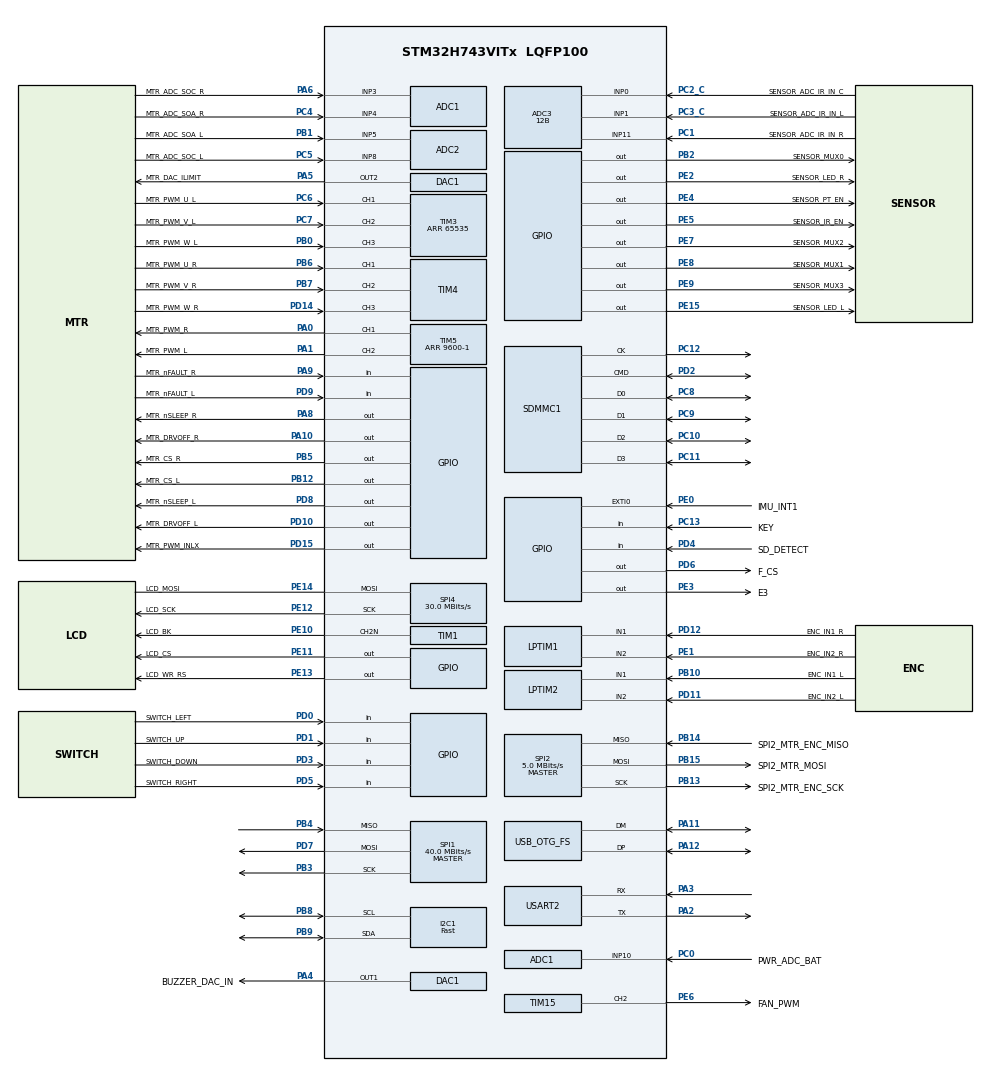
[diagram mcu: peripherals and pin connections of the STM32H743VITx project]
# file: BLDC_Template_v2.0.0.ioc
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ADC1.Channel-3\#ChannelRegularConversion=ADC_CHANNEL_10
ADC1.ClockPrescaler=ADC_CLOCK_ASYNC_DIV4
ADC1.ConversionDataManagement=ADC_CONVERSIONDATA_DMA_CIRCULAR
ADC1.EOCSelection=ADC_EOC_SEQ_CONV
ADC1.EnableInjectedConversion=ENABLE
ADC1.EnableInjectedOversampling=ENABLE
ADC1.ExternalTrigConv=ADC_EXTERNALTRIG_T4_TRGO
ADC1.ExternalTrigInjecConv=ADC_EXTERNALTRIGINJEC_T4_TRGO
ADC1.InjNumberOfConversion=2
ADC1.InjOversamplingRatio=1
ADC1.InjOversamplingRightShift=ADC_RIGHTBITSHIFT_NONE
ADC1.InjectedChannel-6\#ChannelInjectedConversion=ADC_CHANNEL_4
ADC1.InjectedChannel-7\#ChannelInjectedConversion=ADC_CHANNEL_3
ADC1.InjectedOffsetNumber-6\#ChannelInjectedConversion=ADC_OFFSET_NONE
ADC1.InjectedOffsetNumber-7\#ChannelInjectedConversion=ADC_OFFSET_NONE
ADC1.InjectedOffsetSaturation-6\#ChannelInjectedConversion=DISABLE
ADC1.InjectedOffsetSaturation-7\#ChannelInjectedConversion=DISABLE
ADC1.InjectedOffsetSignedSaturation-6\#ChannelInjectedConversion=DISABLE
ADC1.InjectedOffsetSignedSaturation-7\#ChannelInjectedConversion=DISABLE
ADC1.InjectedRank-6\#ChannelInjectedConversion=1
ADC1.InjectedRank-7\#ChannelInjectedConversion=2
ADC1.InjectedSamplingTime-6\#ChannelInjectedConversion=ADC_SAMPLETIME_8CYCLES_5
ADC1.InjectedSamplingTime-7\#ChannelInjectedConversion=ADC_SAMPLETIME_8CYCLES_5
ADC1.NbrOfConversion=1
ADC1.NbrOfConversionFlag=1
ADC1.OffsetNumber-3\#ChannelRegularConversion=ADC_OFFSET_NONE
ADC1.OffsetSignedSaturation-3\#ChannelRegularConversion=DISABLE
ADC1.OversamplingMode=ENABLE
ADC1.Rank-3\#ChannelRegularConversion=1
ADC1.Ratio=4
ADC1.RightBitShift=ADC_RIGHTBITSHIFT_2
ADC1.SamplingTime-3\#ChannelRegularConversion=ADC_SAMPLETIME_16CYCLES_5
ADC1.master=1
ADC2.Channel-2\#ChannelRegularConversion=ADC_CHANNEL_10
ADC2.ClockPrescaler=ADC_CLOCK_ASYNC_DIV4
ADC2.ConversionDataManagement=ADC_CONVERSIONDATA_DMA_CIRCULAR
ADC2.EOCSelection=ADC_EOC_SEQ_CONV
ADC2.EnableInjectedConversion=ENABLE
ADC2.EnableInjectedOversampling=ENABLE
ADC2.ExternalTrigConv=ADC_EXTERNALTRIG_T3_TRGO
ADC2.ExternalTrigInjecConv=ADC_EXTERNALTRIGINJEC_T3_TRGO
ADC2.InjNumberOfConversion=2
ADC2.InjOversamplingRatio=1
ADC2.InjOversamplingRightShift=ADC_RIGHTBITSHIFT_NONE
ADC2.InjectedChannel-5\#ChannelInjectedConversion=ADC_CHANNEL_5
ADC2.InjectedChannel-6\#ChannelInjectedConversion=ADC_CHANNEL_8
ADC2.InjectedOffsetNumber-5\#ChannelInjectedConversion=ADC_OFFSET_NONE
ADC2.InjectedOffsetNumber-6\#ChannelInjectedConversion=ADC_OFFSET_NONE
ADC2.InjectedOffsetSaturation-5\#ChannelInjectedConversion=DISABLE
ADC2.InjectedOffsetSaturation-6\#ChannelInjectedConversion=DISABLE
ADC2.InjectedOffsetSignedSaturation-5\#ChannelInjectedConversion=DISABLE
ADC2.InjectedOffsetSignedSaturation-6\#ChannelInjectedConversion=DISABLE
ADC2.InjectedRank-5\#ChannelInjectedConversion=1
ADC2.InjectedRank-6\#ChannelInjectedConversion=2
ADC2.InjectedSamplingTime-5\#ChannelInjectedConversion=ADC_SAMPLETIME_8CYCLES_5
ADC2.InjectedSamplingTime-6\#ChannelInjectedConversion=ADC_SAMPLETIME_8CYCLES_5
ADC2.NbrOfConversion=1
ADC2.NbrOfConversionFlag=1
ADC2.OffsetNumber-2\#ChannelRegularConversion=ADC_OFFSET_NONE
ADC2.OffsetSignedSaturation-2\#ChannelRegularConversion=DISABLE
ADC2.OversamplingMode=ENABLE
ADC2.Rank-2\#ChannelRegularConversion=1
ADC2.Ratio=4
ADC2.RightBitShift=ADC_RIGHTBITSHIFT_2
ADC2.SamplingTime-2\#ChannelRegularConversion=ADC_SAMPLETIME_16CYCLES_5
ADC3.Channel-10\#ChannelRegularConversion=ADC_CHANNEL_1
ADC3.Channel-11\#ChannelRegularConversion=ADC_CHANNEL_11
ADC3.Channel-2\#ChannelRegularConversion=ADC_CHANNEL_0
ADC3.Channel-3\#ChannelRegularConversion=ADC_CHANNEL_0
ADC3.Channel-4\#ChannelRegularConversion=ADC_CHANNEL_0
ADC3.Channel-5\#ChannelRegularConversion=ADC_CHANNEL_0
ADC3.Channel-6\#ChannelRegularConversion=ADC_CHANNEL_0
ADC3.Channel-7\#ChannelRegularConversion=ADC_CHANNEL_0
ADC3.Channel-8\#ChannelRegularConversion=ADC_CHANNEL_0
ADC3.Channel-9\#ChannelRegularConversion=ADC_CHANNEL_0
ADC3.ClockPrescaler=ADC_CLOCK_ASYNC_DIV4
ADC3.ContinuousConvMode=DISABLE
ADC3.ConversionDataManagement=ADC_CONVERSIONDATA_DMA_CIRCULAR
ADC3.DiscontinuousConvMode=ENABLE
ADC3.EOCSelection=ADC_EOC_SINGLE_CONV
ADC3.ExternalTrigConv=ADC_EXTERNALTRIG_T2_TRGO
ADC3.NbrOfConversion=10
ADC3.NbrOfConversionFlag=1
ADC3.OffsetNumber-10\#ChannelRegularConversion=ADC_OFFSET_NONE
ADC3.OffsetNumber-11\#ChannelRegularConversion=ADC_OFFSET_NONE
ADC3.OffsetNumber-2\#ChannelRegularConversion=ADC_OFFSET_NONE
ADC3.OffsetNumber-3\#ChannelRegularConversion=ADC_OFFSET_NONE
ADC3.OffsetNumber-4\#ChannelRegularConversion=ADC_OFFSET_NONE
ADC3.OffsetNumber-5\#ChannelRegularConversion=ADC_OFFSET_NONE
ADC3.OffsetNumber-6\#ChannelRegularConversion=ADC_OFFSET_NONE
ADC3.OffsetNumber-7\#ChannelRegularConversion=ADC_OFFSET_NONE
ADC3.OffsetNumber-8\#ChannelRegularConversion=ADC_OFFSET_NONE
ADC3.OffsetNumber-9\#ChannelRegularConversion=ADC_OFFSET_NONE
ADC3.OffsetSignedSaturation-2\#ChannelRegularConversion=DISABLE
ADC3.Overrun=ADC_OVR_DATA_PRESERVED
ADC3.OversamplingMode=ENABLE
ADC3.OversamplingStopReset=ADC_REGOVERSAMPLING_RESUMED_MODE
ADC3.Rank-10\#ChannelRegularConversion=9
ADC3.Rank-11\#ChannelRegularConversion=10
ADC3.Rank-2\#ChannelRegularConversion=1
ADC3.Rank-3\#ChannelRegularConversion=2
ADC3.Rank-4\#ChannelRegularConversion=3
ADC3.Rank-5\#ChannelRegularConversion=4
ADC3.Rank-6\#ChannelRegularConversion=5
ADC3.Rank-7\#ChannelRegularConversion=6
ADC3.Rank-8\#ChannelRegularConversion=7
ADC3.Rank-9\#ChannelRegularConversion=8
ADC3.Ratio=2
ADC3.Resolution=ADC_RESOLUTION_12B
ADC3.RightBitShift=ADC_RIGHTBITSHIFT_1
ADC3.SamplingTime-10\#ChannelRegularConversion=ADC_SAMPLETIME_8CYCLES_5
ADC3.SamplingTime-11\#ChannelRegularConversion=ADC_SAMPLETIME_8CYCLES_5
ADC3.SamplingTime-2\#ChannelRegularConversion=ADC_SAMPLETIME_8CYCLES_5
ADC3.SamplingTime-3\#ChannelRegularConversion=ADC_SAMPLETIME_8CYCLES_5
ADC3.SamplingTime-4\#ChannelRegularConversion=ADC_SAMPLETIME_8CYCLES_5
ADC3.SamplingTime-5\#ChannelRegularConversion=ADC_SAMPLETIME_8CYCLES_5
ADC3.SamplingTime-6\#ChannelRegularConversion=ADC_SAMPLETIME_8CYCLES_5
ADC3.SamplingTime-7\#ChannelRegularConversion=ADC_SAMPLETIME_8CYCLES_5
ADC3.SamplingTime-8\#ChannelRegularConversion=ADC_SAMPLETIME_8CYCLES_5
ADC3.SamplingTime-9\#ChannelRegularConversion=ADC_SAMPLETIME_8CYCLES_5
ADC3.TriggeredMode=ADC_TRIGGEREDMODE_SINGLE_TRIGGER
Bdma.ADC3.0.Direction=DMA_PERIPH_TO_MEMORY
Bdma.ADC3.0.EventEnable=DISABLE
Bdma.ADC3.0.Instance=BDMA_Channel0
Bdma.ADC3.0.MemDataAlignment=DMA_MDATAALIGN_HALFWORD
Bdma.ADC3.0.MemInc=DMA_MINC_ENABLE
Bdma.ADC3.0.Mode=DMA_CIRCULAR
Bdma.ADC3.0.PeriphDataAlignment=DMA_PDATAALIGN_HALFWORD
Bdma.ADC3.0.PeriphInc=DMA_PINC_DISABLE
Bdma.ADC3.0.Polarity=HAL_DMAMUX_REQ_GEN_RISING
Bdma.ADC3.0.Priority=DMA_PRIORITY_VERY_HIGH
Bdma.ADC3.0.RequestNumber=1
Bdma.ADC3.0.SignalID=NONE
Bdma.ADC3.0.SyncEnable=DISABLE
Bdma.ADC3.0.SyncPolarity=HAL_DMAMUX_SYNC_NO_EVENT
Bdma.ADC3.0.SyncRequestNumber=1
Bdma.ADC3.0.SyncSignalID=NONE
Bdma.Request0=ADC3
Bdma.RequestsNb=1
CORTEX_M7.AccessPermission_S-Cortex_Memory_Protection_Unit_Region1_Settings_S=MPU_REGION_FULL_ACCESS
CORTEX_M7.AccessPermission_Spec=MPU_REGION_FULL_ACCESS
CORTEX_M7.BaseAddress_S-Cortex_Memory_Protection_Unit_Region1_Settings_S=0x38000000
CORTEX_M7.BaseAddress_Spec=0x30040000
CORTEX_M7.CPU_DCache=Enabled
CORTEX_M7.CPU_ICache=Enabled
CORTEX_M7.DisableExec_S-Cortex_Memory_Protection_Unit_Region1_Settings_S=MPU_INSTRUCTION_ACCESS_DISABLE
CORTEX_M7.Enable_S-Cortex_Memory_Protection_Unit_Region1_Settings_S=MPU_REGION_ENABLE
CORTEX_M7.IsShareable_S-Cortex_Memory_Protection_Unit_Region1_Settings_S=MPU_ACCESS_SHAREABLE
CORTEX_M7.MPU_Control=MPU_PRIVILEGED_DEFAULT
CORTEX_M7.Size_S-Cortex_Memory_Protection_Unit_Region1_Settings_S=MPU_REGION_SIZE_64KB
CORTEX_M7.Size_Spec=MPU_REGION_SIZE_32KB
CORTEX_M7.SubRegionDisable_Spec=0x0
CORTEX_M7.TypeExtField_S-Cortex_Memory_Protection_Unit_Region1_Settings_S=MPU_TEX_LEVEL1
CORTEX_M7.TypeExtField_Spec=MPU_TEX_LEVEL1
CORTEX_M7.default_mode_Activation=1
DAC1.DAC_Channel-DAC_OUT1=DAC_CHANNEL_1
DAC1.DAC_Channel-DAC_OUT2=DAC_CHANNEL_2
DAC1.DAC_Trigger-DAC_OUT1=DAC_TRIGGER_T6_TRGO
Dma.ADC1.3.Direction=DMA_PERIPH_TO_MEMORY
Dma.ADC1.3.EventEnable=DISABLE
Dma.ADC1.3.FIFOMode=DMA_FIFOMODE_DISABLE
Dma.ADC1.3.Instance=DMA1_Stream3
Dma.ADC1.3.MemDataAlignment=DMA_MDATAALIGN_HALFWORD
Dma.ADC1.3.MemInc=DMA_MINC_ENABLE
Dma.ADC1.3.Mode=DMA_CIRCULAR
Dma.ADC1.3.PeriphDataAlignment=DMA_PDATAALIGN_HALFWORD
Dma.ADC1.3.PeriphInc=DMA_PINC_DISABLE
Dma.ADC1.3.Polarity=HAL_DMAMUX_REQ_GEN_RISING
Dma.ADC1.3.Priority=DMA_PRIORITY_VERY_HIGH
Dma.ADC1.3.RequestNumber=1
Dma.ADC1.3.SignalID=NONE
Dma.ADC1.3.SyncEnable=DISABLE
Dma.ADC1.3.SyncPolarity=HAL_DMAMUX_SYNC_NO_EVENT
Dma.ADC1.3.SyncRequestNumber=1
Dma.ADC1.3.SyncSignalID=NONE
Dma.ADC2.2.Direction=DMA_PERIPH_TO_MEMORY
Dma.ADC2.2.EventEnable=DISABLE
Dma.ADC2.2.FIFOMode=DMA_FIFOMODE_DISABLE
Dma.ADC2.2.Instance=DMA1_Stream2
Dma.ADC2.2.MemDataAlignment=DMA_MDATAALIGN_HALFWORD
Dma.ADC2.2.MemInc=DMA_MINC_ENABLE
Dma.ADC2.2.Mode=DMA_CIRCULAR
Dma.ADC2.2.PeriphDataAlignment=DMA_PDATAALIGN_HALFWORD
Dma.ADC2.2.PeriphInc=DMA_PINC_DISABLE
Dma.ADC2.2.Polarity=HAL_DMAMUX_REQ_GEN_RISING
Dma.ADC2.2.Priority=DMA_PRIORITY_VERY_HIGH
Dma.ADC2.2.RequestNumber=1
Dma.ADC2.2.SignalID=NONE
Dma.ADC2.2.SyncEnable=DISABLE
Dma.ADC2.2.SyncPolarity=HAL_DMAMUX_SYNC_NO_EVENT
Dma.ADC2.2.SyncRequestNumber=1
Dma.ADC2.2.SyncSignalID=NONE
Dma.DAC1_CH1.1.Direction=DMA_MEMORY_TO_PERIPH
Dma.DAC1_CH1.1.EventEnable=DISABLE
Dma.DAC1_CH1.1.FIFOMode=DMA_FIFOMODE_DISABLE
Dma.DAC1_CH1.1.Instance=DMA1_Stream1
Dma.DAC1_CH1.1.MemDataAlignment=DMA_MDATAALIGN_WORD
Dma.DAC1_CH1.1.MemInc=DMA_MINC_ENABLE
Dma.DAC1_CH1.1.Mode=DMA_CIRCULAR
Dma.DAC1_CH1.1.PeriphDataAlignment=DMA_PDATAALIGN_WORD
Dma.DAC1_CH1.1.PeriphInc=DMA_PINC_DISABLE
Dma.DAC1_CH1.1.Polarity=HAL_DMAMUX_REQ_GEN_RISING
Dma.DAC1_CH1.1.Priority=DMA_PRIORITY_LOW
Dma.DAC1_CH1.1.RequestNumber=1
Dma.DAC1_CH1.1.SignalID=NONE
Dma.DAC1_CH1.1.SyncEnable=DISABLE
Dma.DAC1_CH1.1.SyncPolarity=HAL_DMAMUX_SYNC_NO_EVENT
Dma.DAC1_CH1.1.SyncRequestNumber=1
Dma.DAC1_CH1.1.SyncSignalID=NONE
Dma.I2C1_RX.4.Direction=DMA_PERIPH_TO_MEMORY
Dma.I2C1_RX.4.EventEnable=DISABLE
Dma.I2C1_RX.4.FIFOMode=DMA_FIFOMODE_DISABLE
Dma.I2C1_RX.4.Instance=DMA1_Stream4
Dma.I2C1_RX.4.MemDataAlignment=DMA_MDATAALIGN_BYTE
Dma.I2C1_RX.4.MemInc=DMA_MINC_ENABLE
Dma.I2C1_RX.4.Mode=DMA_NORMAL
Dma.I2C1_RX.4.PeriphDataAlignment=DMA_PDATAALIGN_BYTE
Dma.I2C1_RX.4.PeriphInc=DMA_PINC_DISABLE
Dma.I2C1_RX.4.Polarity=HAL_DMAMUX_REQ_GEN_RISING
Dma.I2C1_RX.4.Priority=DMA_PRIORITY_LOW
Dma.I2C1_RX.4.RequestNumber=1
Dma.I2C1_RX.4.SignalID=NONE
Dma.I2C1_RX.4.SyncEnable=DISABLE
Dma.I2C1_RX.4.SyncPolarity=HAL_DMAMUX_SYNC_NO_EVENT
Dma.I2C1_RX.4.SyncRequestNumber=1
Dma.I2C1_RX.4.SyncSignalID=NONE
Dma.Request0=SPI4_TX
Dma.Request1=DAC1_CH1
Dma.Request2=ADC2
Dma.Request3=ADC1
Dma.Request4=I2C1_RX
Dma.SPI4_TX.0.Direction=DMA_MEMORY_TO_PERIPH
Dma.SPI4_TX.0.EventEnable=DISABLE
Dma.SPI4_TX.0.FIFOMode=DMA_FIFOMODE_ENABLE
Dma.SPI4_TX.0.FIFOThreshold=DMA_FIFO_THRESHOLD_FULL
Dma.SPI4_TX.0.Instance=DMA1_Stream0
Dma.SPI4_TX.0.MemBurst=DMA_MBURST_SINGLE
Dma.SPI4_TX.0.MemDataAlignment=DMA_MDATAALIGN_BYTE
Dma.SPI4_TX.0.MemInc=DMA_MINC_ENABLE
Dma.SPI4_TX.0.Mode=DMA_NORMAL
Dma.SPI4_TX.0.PeriphBurst=DMA_PBURST_SINGLE
Dma.SPI4_TX.0.PeriphDataAlignment=DMA_PDATAALIGN_BYTE
Dma.SPI4_TX.0.PeriphInc=DMA_PINC_DISABLE
Dma.SPI4_TX.0.Polarity=HAL_DMAMUX_REQ_GEN_RISING
Dma.SPI4_TX.0.Priority=DMA_PRIORITY_LOW
Dma.SPI4_TX.0.RequestNumber=1
Dma.SPI4_TX.0.SignalID=NONE
Dma.SPI4_TX.0.SyncEnable=DISABLE
Dma.SPI4_TX.0.SyncPolarity=HAL_DMAMUX_SYNC_NO_EVENT
Dma.SPI4_TX.0.SyncRequestNumber=1
Dma.SPI4_TX.0.SyncSignalID=NONE
FATFS.BSP.number=1
FATFS.USE_DMA_CODE_SD=1
FATFS._FS_EXFAT=1
FATFS._MAX_SS=4096
FATFS._USE_LFN=1
FATFS0.BSP.STBoard=false
FATFS0.BSP.api=Unknown
FATFS0.BSP.instance=PD4
FATFS0.BSP.ip=GPIO
FATFS0.BSP.mode=Input
FATFS0.BSP.name=Detect_SDIO
FATFS0.BSP.solution=PD4
I2C1.I2C_Speed_Mode=I2C_Fast
I2C1.Timing=0x30C8172C
LPTIM1.ULPClockPolarity=LPTIM_CLOCKPOLARITY_RISING_FALLING
LPTIM2.ULPClockPolarity=LPTIM_CLOCKPOLARITY_RISING_FALLING
LPTIM3.ClockPrescaler=LPTIM_PRESCALER_DIV32
Mcu.Family=STM32H7
Mcu.Name=STM32H743VITx
Mcu.Package=LQFP100
Mcu.UserConstants=CUSTOM_HID_EPOUT_SIZE,0x40U;CUSTOM_HID_EPIN_SIZE,0x40U
NVIC.ADC3_IRQn=true\:0\:0\:false\:false\:true\:true\:true\:true
NVIC.ADC_IRQn=true\:0\:0\:false\:false\:true\:true\:true\:true
NVIC.BDMA_Channel0_IRQn=true\:0\:0\:false\:false\:true\:false\:true\:true
NVIC.DMA1_Stream0_IRQn=true\:0\:0\:false\:false\:true\:false\:true\:true
NVIC.DMA1_Stream1_IRQn=true\:0\:0\:false\:false\:true\:false\:true\:true
NVIC.DMA1_Stream2_IRQn=true\:0\:0\:false\:false\:true\:false\:true\:true
NVIC.DMA1_Stream3_IRQn=true\:0\:0\:false\:false\:true\:false\:true\:true
NVIC.DMA1_Stream4_IRQn=true\:0\:0\:false\:false\:true\:false\:true\:true
NVIC.EXTI0_IRQn=true\:0\:0\:false\:false\:true\:true\:true\:true
NVIC.I2C1_ER_IRQn=true\:0\:0\:false\:false\:true\:true\:true\:true
NVIC.I2C1_EV_IRQn=true\:0\:0\:false\:false\:true\:true\:true\:true
NVIC.LPTIM3_IRQn=true\:0\:0\:false\:false\:true\:true\:true\:true
NVIC.OTG_FS_IRQn=true\:0\:0\:false\:false\:true\:false\:true\:true
NVIC.PriorityGroup=NVIC_PRIORITYGROUP_4
NVIC.SDMMC1_IRQn=true\:0\:0\:false\:false\:true\:true\:true\:true
NVIC.SPI4_IRQn=true\:0\:0\:false\:false\:true\:false\:true\:true
NVIC.TIM6_DAC_IRQn=true\:0\:0\:false\:false\:true\:true\:true\:true
NVIC.TIM7_IRQn=true\:0\:0\:false\:false\:true\:true\:true\:true
NVIC.TIM8_TRG_COM_TIM14_IRQn=true\:0\:0\:false\:false\:true\:true\:true\:true
NVIC.TIM8_UP_TIM13_IRQn=true\:0\:0\:false\:false\:true\:true\:true\:true
PA0.GPIO_Label=MTR_PWM_R
PA0.Signal=S_TIM5_CH1
PA1.GPIO_Label=MTR_PWM_L
PA1.Signal=S_TIM5_CH2
PA10.GPIO_Label=MTR_DRVOFF_R
PA10.Signal=GPIO_Output
PA11.Mode=Device_Only
PA11.Signal=USB_OTG_FS_DM
PA12.Mode=Device_Only
PA12.Signal=USB_OTG_FS_DP
PA13\ (JTMS/SWDIO).Mode=Serial_Wire
PA13\ (JTMS/SWDIO).Signal=DEBUG_JTMS-SWDIO
PA14\ (JTCK/SWCLK).Mode=Serial_Wire
PA14\ (JTCK/SWCLK).Signal=DEBUG_JTCK-SWCLK
PA2.Mode=Asynchronous
PA2.Signal=USART2_TX
PA3.Mode=Asynchronous
PA3.Signal=USART2_RX
PA4.GPIO_Label=BUZZER_DAC_IN
PA4.Signal=COMP_DAC11_group
PA5.GPIO_Label=MTR_DAC_ILIMIT
PA5.Signal=COMP_DAC12_group
PA6.GPIO_Label=MTR_ADC_SOC_R
PA6.Signal=ADCx_INP3
PA7.GPIO_Label=DVP_PWDN
PA7.Signal=EVENTOUT
PA8.GPIO_Label=MTR_nSLEEP_R
PA8.Signal=GPIO_Output
PA9.GPIO_Label=MTR_nFAULT_R
PA9.GPIO_PuPd=GPIO_PULLUP
PA9.Signal=GPIO_Input
PB0.GPIO_Label=MTR_PWM_W_L
PB0.Signal=S_TIM3_CH3
PB1.GPIO_Label=MTR_ADC_SOA_L
PB1.Signal=ADCx_INP5
PB10.GPIO_Label=ENC_IN1_L
PB10.Mode=Encoder_mode_occur1
PB10.Signal=LPTIM2_IN1
PB12.GPIO_Label=MTR_CS_L
PB12.Signal=GPIO_Output
PB13.GPIO_Label=SPI2_MTR_ENC_SCK
PB13.Mode=Full_Duplex_Master
PB13.Signal=SPI2_SCK
PB14.GPIO_Label=SPI2_MTR_ENC_MISO
PB14.GPIO_PuPd=GPIO_PULLUP
PB14.Mode=Full_Duplex_Master
PB14.Signal=SPI2_MISO
PB15.GPIO_Label=SPI2_MTR_MOSI
PB15.Mode=Full_Duplex_Master
PB15.Signal=SPI2_MOSI
PB2.GPIO_Label=SENSOR_MUX0
PB2.GPIO_PuPd=GPIO_PULLDOWN
PB2.Signal=GPIO_Output
PB3\ (JTDO/TRACESWO).Mode=Full_Duplex_Master
PB3\ (JTDO/TRACESWO).Signal=SPI1_SCK
PB4\ (NJTRST).GPIO_PuPd=GPIO_PULLUP
PB4\ (NJTRST).Mode=Full_Duplex_Master
PB4\ (NJTRST).Signal=SPI1_MISO
PB5.GPIO_Label=MTR_CS_R
PB5.Signal=GPIO_Output
PB6.GPIO_Label=MTR_PWM_U_R
PB6.Signal=S_TIM4_CH1
PB7.GPIO_Label=MTR_PWM_V_R
PB7.Signal=S_TIM4_CH2
PB8.GPIO_Pu=GPIO_PULLUP
PB8.Mode=I2C
PB8.Signal=I2C1_SCL
PB9.GPIO_Pu=GPIO_PULLUP
PB9.Mode=I2C
PB9.Signal=I2C1_SDA
PC0.GPIO_Label=PWR_ADC_BAT
PC0.Signal=ADCx_INP10
PC1.GPIO_Label=SENSOR_ADC_IR_IN_R
PC1.GPIO_Pd=GPIO_NOPULL
PC1.Signal=ADCx_INP11
PC10.Mode=SD_4_bits_Wide_bus
PC10.Signal=SDMMC1_D2
PC11.Mode=SD_4_bits_Wide_bus
PC11.Signal=SDMMC1_D3
PC12.Mode=SD_4_bits_Wide_bus
PC12.Signal=SDMMC1_CK
PC13.GPIO_Label=KEY
PC13.GPIO_PuPd=GPIO_PULLDOWN
PC13.Signal=GPIO_Input
PC14-OSC32_IN\ (OSC32_IN).Mode=LSE-External-Oscillator
PC14-OSC32_IN\ (OSC32_IN).Signal=RCC_OSC32_IN
PC15-OSC32_OUT\ (OSC32_OUT).Mode=LSE-External-Oscillator
PC15-OSC32_OUT\ (OSC32_OUT).Signal=RCC_OSC32_OUT
PC2_C.GPIO_Label=SENSOR_ADC_IR_IN_C
PC2_C.GPIO_Pd=GPIO_NOPULL
PC2_C.Mode=IN0-Single-Ended
PC2_C.Signal=ADC3_INP0
PC3_C.GPIO_Label=SENSOR_ADC_IR_IN_L
PC3_C.GPIO_Pd=GPIO_NOPULL
PC3_C.Mode=IN1-Single-Ended
PC3_C.Signal=ADC3_INP1
PC4.GPIO_Label=MTR_ADC_SOA_R
PC4.Signal=ADCx_INP4
PC5.GPIO_Label=MTR_ADC_SOC_L
PC5.Signal=ADCx_INP8
PC6.GPIO_Label=MTR_PWM_U_L
PC6.Signal=S_TIM3_CH1
PC7.GPIO_Label=MTR_PWM_V_L
PC7.Signal=S_TIM3_CH2
PC8.Mode=SD_4_bits_Wide_bus
PC8.Signal=SDMMC1_D0
PC9.Mode=SD_4_bits_Wide_bus
PC9.Signal=SDMMC1_D1
PD0.GPIO_Label=SWITCH_LEFT
PD0.GPIO_PuPd=GPIO_PULLDOWN
PD0.Signal=GPIO_Input
PD1.GPIO_Label=SWITCH_UP
PD1.GPIO_PuPd=GPIO_PULLDOWN
PD1.Signal=GPIO_Input
PD10.GPIO_Label=MTR_DRVOFF_L
PD10.Signal=GPIO_Output
PD11.GPIO_Label=ENC_IN2_L
PD11.Mode=Encoder_mode_occur1
PD11.Signal=LPTIM2_IN2
PD12.GPIO_Label=ENC_IN1_R
PD12.Mode=Encoder_mode_occur1
PD12.Signal=LPTIM1_IN1
PD14.GPIO_Label=MTR_PWM_W_R
PD14.Signal=S_TIM4_CH3
PD15.GPIO_Label=MTR_PWM_INLX
PD15.Signal=GPIO_Output
PD2.Mode=SD_4_bits_Wide_bus
PD2.Signal=SDMMC1_CMD
PD3.GPIO_Label=SWITCH_DOWN
PD3.GPIO_PuPd=GPIO_PULLDOWN
PD3.Signal=GPIO_Input
PD4.GPIO_Label=SD_DETECT
PD4.GPIO_PuPd=GPIO_PULLUP
PD4.Signal=GPIO_Input
PD5.GPIO_Label=SWITCH_RIGHT
PD5.GPIO_PuPd=GPIO_PULLDOWN
PD5.Signal=GPIO_Input
PD6.GPIO_Label=F_CS
PD6.GPIO_PuPd=GPIO_PULLUP
PD6.GPIO_Speed=GPIO_SPEED_FREQ_HIGH
PD6.Signal=GPIO_Output
PD7.GPIO_PuPd=GPIO_PULLUP
PD7.Mode=Full_Duplex_Master
PD7.Signal=SPI1_MOSI
PD8.GPIO_Label=MTR_nSLEEP_L
PD8.Signal=GPIO_Output
PD9.GPIO_Label=MTR_nFAULT_L
PD9.GPIO_PuPd=GPIO_PULLUP
PD9.Signal=GPIO_Input
PE0.GPIO_Label=IMU_INT1
PE0.Signal=GPXTI0
PE1.GPIO_Label=ENC_IN2_R
PE1.Mode=Encoder_mode_occur1
PE1.Signal=LPTIM1_IN2
PE10.GPIO_Label=LCD_BK
PE10.Mode=PWM Generation2 CH2N
PE10.Signal=TIM1_CH2N
PE11.GPIO_Label=LCD_CS
PE11.Signal=GPIO_Output
PE12.GPIO_Label=LCD_SCK
PE12.GPIO_Speed=GPIO_SPEED_FREQ_HIGH
PE12.Mode=Simplex_Bidirectional_Master
PE12.Signal=SPI4_SCK
PE13.GPIO_Label=LCD_WR_RS
PE13.Signal=GPIO_Output
PE14.GPIO_Label=LCD_MOSI
PE14.GPIO_Speed=GPIO_SPEED_FREQ_HIGH
PE14.Mode=Simplex_Bidirectional_Master
PE14.Signal=SPI4_MOSI
PE15.GPIO_Label=SENSOR_LED_L
PE15.Signal=GPIO_Output
PE2.GPIO_Label=SENSOR_LED_R
PE2.Signal=GPIO_Output
PE3.GPIO_Label=E3
PE3.GPIO_ModeDefaultOutputPP=GPIO_MODE_OUTPUT_PP
PE3.GPIO_PuPd=GPIO_NOPULL
PE3.PinState=GPIO_PIN_SET
PE3.Signal=GPIO_Output
PE4.GPIO_Label=SENSOR_PT_EN
PE4.Signal=GPIO_Output
PE5.GPIO_Label=SENSOR_IR_EN
PE5.Signal=GPIO_Output
PE6.GPIO_Label=FAN_PWM
PE6.Signal=S_TIM15_CH2
PE7.GPIO_Label=SENSOR_MUX2
PE7.GPIO_ModeDefaultOutputPP=GPIO_MODE_OUTPUT_PP
PE7.GPIO_PuPd=GPIO_PULLDOWN
PE7.Signal=GPIO_Output
PE8.GPIO_Label=SENSOR_MUX1
PE8.GPIO_PuPd=GPIO_PULLDOWN
PE8.Signal=GPIO_Output
PE9.GPIO_Label=SENSOR_MUX3
PE9.GPIO_PuPd=GPIO_PULLDOWN
PE9.Signal=GPIO_Output
PH0-OSC_IN\ (PH0).Mode=HSE-External-Oscillator
PH0-OSC_IN\ (PH0).Signal=RCC_OSC_IN
PH1-OSC_OUT\ (PH1).Mode=HSE-External-Oscillator
PH1-OSC_OUT\ (PH1).Signal=RCC_OSC_OUT
ProjectManager.HeapSize=0x200
ProjectManager.StackSize=0x400
ProjectManager.TargetToolchain=STM32CubeIDE
RCC.ADCFreq_Value=100000000
RCC.APB1Freq_Value=120000000
RCC.APB2Freq_Value=120000000
RCC.APB3Freq_Value=120000000
RCC.APB4Freq_Value=120000000
RCC.CortexFreq_Value=480000000
RCC.D1PPRE=RCC_APB3_DIV2
RCC.D2PPRE1=RCC_APB1_DIV2
RCC.D2PPRE2=RCC_APB2_DIV2
RCC.D3PPRE=RCC_APB4_DIV2
RCC.DIVM1=5
RCC.DIVM2=2
RCC.DIVN1=192
RCC.DIVN2=40
RCC.DIVP2=5
RCC.DIVQ1=12
RCC.HCLKFreq_Value=240000000
RCC.HPRE=RCC_HCLK_DIV2
RCC.HSE_VALUE=25000000
RCC.LPTIM345CLockSelection=RCC_LPTIM345CLKSOURCE_LSI
RCC.LSE_Drive_Capability=RCC_LSEDRIVE_HIGH
RCC.LSE_Timout=500
RCC.PLL2FRACN=0
RCC.PLL3FRACN=0
RCC.PLLFRACN=0
RCC.PLLSourceVirtual=RCC_PLLSOURCE_HSE
RCC.RCC_RTC_Clock_Source_FROM_HSE=RCC_RTCCLKSOURCE_HSE_DIV50
RCC.RTCClockSelection=RCC_RTCCLKSOURCE_LSE
RCC.SYSCLKFreq_VALUE=480000000
RCC.SYSCLKSource=RCC_SYSCLKSOURCE_PLLCLK
RCC.SupplySource=PWR_LDO_SUPPLY
RCC.USBCLockSelection=RCC_USBCLKSOURCE_HSI48
RCC.USBFreq_Value=48000000
SDMMC1.ClockDiv=5
SH.ADCx_INP10.0=ADC1_INP10,IN10-Single-Ended
SH.ADCx_INP10.1=ADC2_INP10,IN10-Single-Ended
SH.ADCx_INP11.0=ADC3_INP11,IN11-Single-Ended
SH.ADCx_INP3.0=ADC1_INP3,IN3-Single-Ended
SH.ADCx_INP4.0=ADC1_INP4,IN4-Single-Ended
SH.ADCx_INP5.0=ADC2_INP5,IN5-Single-Ended
SH.ADCx_INP8.0=ADC2_INP8,IN8-Single-Ended
SH.COMP_DAC11_group.0=DAC1_OUT1,DAC_OUT1
SH.COMP_DAC12_group.0=DAC1_OUT2,DAC_OUT2
SH.S_TIM15_CH2.0=TIM15_CH2,PWM Generation2 CH2
SH.S_TIM3_CH1.0=TIM3_CH1,Xored_Inputs_Hall_Sensor_Interface
SH.S_TIM3_CH2.0=TIM3_CH2,Xored_Inputs_Hall_Sensor_Interface
SH.S_TIM3_CH3.0=TIM3_CH3,Xored_Inputs_Hall_Sensor_Interface
SH.S_TIM4_CH1.0=TIM4_CH1,Xored_Inputs_Hall_Sensor_Interface
SH.S_TIM4_CH2.0=TIM4_CH2,Xored_Inputs_Hall_Sensor_Interface
SH.S_TIM4_CH3.0=TIM4_CH3,Xored_Inputs_Hall_Sensor_Interface
SH.S_TIM5_CH1.0=TIM5_CH1,PWM Generation1 CH1
SH.S_TIM5_CH2.0=TIM5_CH2,PWM Generation2 CH2
SPI1.BaudRatePrescaler=SPI_BAUDRATEPRESCALER_2
SPI1.CalculateBaudRate=40.0 MBits/s
SPI1.DataSize=SPI_DATASIZE_8BIT
SPI1.Direction=SPI_DIRECTION_2LINES
SPI1.Mode=SPI_MODE_MASTER
SPI1.NSSPMode=SPI_NSS_PULSE_DISABLE
SPI1.VirtualType=VM_MASTER
SPI2.BaudRatePrescaler=SPI_BAUDRATEPRESCALER_16
SPI2.CLKPhase=SPI_PHASE_2EDGE
SPI2.CalculateBaudRate=5.0 MBits/s
SPI2.DataSize=SPI_DATASIZE_8BIT
SPI2.Direction=SPI_DIRECTION_2LINES
SPI2.IOSwap=SPI_IO_SWAP_ENABLE
SPI2.Mode=SPI_MODE_MASTER
SPI2.VirtualType=VM_MASTER
SPI4.BaudRatePrescaler=SPI_BAUDRATEPRESCALER_4
SPI4.CalculateBaudRate=30.0 MBits/s
SPI4.DataSize=SPI_DATASIZE_8BIT
SPI4.Direction=SPI_DIRECTION_1LINE
SPI4.Mode=SPI_MODE_MASTER
SPI4.VirtualType=VM_MASTER
TIM1.Channel-PWM\ Generation2\ CH2N=TIM_CHANNEL_2
TIM1.OCMode_PWM-PWM\ Generation2\ CH2N=TIM_OCMODE_PWM2
TIM1.Period=1000-1
TIM1.Prescaler=24-1
TIM13.Period=500-1
TIM13.Prescaler=240-1
TIM14.Period=500-1
TIM14.Prescaler=240-1
TIM15.Channel-PWM\ Generation2\ CH2=TIM_CHANNEL_2
TIM15.Period=1000-1
TIM15.Prescaler=0
TIM2.AutoReloadPreload=TIM_AUTORELOAD_PRELOAD_ENABLE
TIM2.Period=5-1
TIM2.Prescaler=240-1
TIM2.TIM_MasterOutputTrigger=TIM_TRGO_UPDATE
TIM2.TIM_MasterSlaveMode=TIM_MASTERSLAVEMODE_ENABLE
TIM3.AutoReloadPreload=TIM_AUTORELOAD_PRELOAD_ENABLE
TIM3.Period=65535
TIM4.AutoReloadPreload=TIM_AUTORELOAD_PRELOAD_ENABLE
TIM5.Channel-PWM\ Generation1\ CH1=TIM_CHANNEL_1
TIM5.Channel-PWM\ Generation2\ CH2=TIM_CHANNEL_2
TIM5.Period=9600-1
TIM6.AutoReloadPreload=TIM_AUTORELOAD_PRELOAD_ENABLE
TIM6.Period=100-1
TIM6.Prescaler=400-1
TIM6.TIM_MasterOutputTrigger=TIM_TRGO_UPDATE
TIM7.Period=25-1
TIM7.Prescaler=240-1
USART2.VirtualMode-Asynchronous=VM_ASYNC
USB_DEVICE.CLASS_NAME_FS=CUSTOM_HID
USB_DEVICE.CONFIGURATION_STRING_CUSTOMHID_FS=STM32 HID Bootloader Config
USB_DEVICE.CUSTOM_HID_FS_BINTERVAL=0x1
USB_DEVICE.INTERFACE_STRING_CUSTOMHID_FS=STM32 HID Bootloader Interface
USB_DEVICE.MANUFACTURER_STRING-CUSTOM_HID_FS=WeAct Studio
USB_DEVICE.PID_CUSTOMHID_FS=22314
USB_DEVICE.PRODUCT_STRING_CUSTOMHID_FS=WeAct Studio HID Bootloader
USB_DEVICE.USBD_CUSTOMHID_OUTREPORT_BUF_SIZE-CUSTOM_HID_FS=64
USB_DEVICE.USBD_CUSTOM_HID_REPORT_DESC_SIZE-CUSTOM_HID_FS=20
USB_DEVICE.USBD_SELF_POWERED-CUSTOM_HID_FS=0
USB_DEVICE.VirtualMode-CUSTOM_HID_FS=CustomHid
USB_DEVICE.VirtualModeFS=Custom_Hid_FS
USB_OTG_FS.VirtualMode=Device_Only
VP_FATFS_VS_SDIO.Mode=SDIO
VP_LPTIM3_VS_LPTIM_counterModeInternalClock.Mode=Counts__internal_clock_event_00
VP_LPTIM4_VS_LPTIM_counterModeInternalClock.Mode=Counts__internal_clock_event_00
VP_MEMORYMAP_VS_MEMORYMAP.Mode=CurAppReg
VP_RNG_VS_RNG.Mode=RNG_Activate
VP_RTC_VS_RTC_Activate.Mode=RTC_Enabled
VP_TIM13_VS_ClockSourceINT.Mode=Enable_Timer
VP_TIM14_VS_ClockSourceINT.Mode=Enable_Timer
VP_TIM15_VS_ClockSourceINT.Mode=Internal
VP_TIM1_VS_ClockSourceINT.Mode=Internal
VP_TIM2_VS_ClockSourceINT.Mode=Internal
VP_TIM2_VS_OPM.Mode=OPM_bit
VP_TIM3_VS_ClockSourceINT.Mode=Internal
VP_TIM4_VS_ClockSourceINT.Mode=Internal
VP_TIM5_VS_ClockSourceINT.Mode=Internal
VP_TIM6_VS_ClockSourceINT.Mode=Enable_Timer
VP_TIM7_VS_ClockSourceINT.Mode=Enable_Timer
VP_USB_DEVICE_VS_USB_DEVICE_CUSTOM_HID_FS.Mode=CUSTOM_HID_FS
board=custom

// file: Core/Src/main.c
/* USER CODE BEGIN Header */
/**
 ******************************************************************************
 * @file           : main.c
 * @brief          : Main program body
 ******************************************************************************
 */
/* USER CODE END Header */
#include "main.h"
#include "adc.h"
#include "bdma.h"
#include "dac.h"
#include "dma.h"
#include "fatfs.h"
#include "i2c.h"
#include "lptim.h"
#include "rng.h"
#include "rtc.h"
#include "sdmmc.h"
#include "spi.h"
#include "tim.h"
#include "usart.h"
#include "gpio.h"

/* USER CODE BEGIN Includes */
#include "user_init.h"
#include "hid_bootloader.h"
#include "usb_device.h"
#include "bootloader.h"
#include "menu.h"

/* USER CODE END Includes */

/* USER CODE BEGIN PV */

/* BDMA 영역(RAM_D3)에 ADC3 수신 버퍼 강제 할당 */

/* USER CODE END PV */

void SystemClock_Config(void);
void PeriphCommonClock_Config(void);
static void MPU_Config(void);

/* USER CODE BEGIN 0 */
void ExitRun0Mode(void) {
}

void LED_Blink(uint32_t delay) {
	HAL_GPIO_WritePin(E3_GPIO_Port, E3_Pin, GPIO_PIN_SET);
	HAL_Delay(delay - 1);
	HAL_GPIO_WritePin(E3_GPIO_Port, E3_Pin, GPIO_PIN_RESET);
	HAL_Delay(delay - 1);
}

void LED_Test() {
	LED_Blink(250);
}
/* USER CODE END 0 */

int main(void)
{

  /* USER CODE BEGIN 1 */
	Check_Bootloader_Request();
  /* USER CODE END 1 */

  /* MPU Configuration--------------------------------------------------------*/
  MPU_Config();

  /* Enable the CPU Cache */

  /* Enable I-Cache---------------------------------------------------------*/
  SCB_EnableICache();

  /* Enable D-Cache---------------------------------------------------------*/
  SCB_EnableDCache();

  /* MCU Configuration--------------------------------------------------------*/

  /* Reset of all peripherals, Initializes the Flash interface and the Systick. */
  HAL_Init();

  /* Configure the system clock */
  SystemClock_Config();

  /* Configure the peripherals common clocks */
  PeriphCommonClock_Config();

  /* Initialize all configured peripherals */
  MX_GPIO_Init();
  MX_DMA_Init();
  MX_BDMA_Init();
  MX_RTC_Init();
  MX_ADC1_Init();
  MX_ADC2_Init();
  MX_ADC3_Init();
  MX_DAC1_Init();
  MX_I2C1_Init();
  MX_LPTIM1_Init();
  MX_LPTIM2_Init();
  MX_SDMMC1_SD_Init();
  MX_SPI1_Init();
  MX_SPI2_Init();
  MX_SPI4_Init();
  MX_TIM1_Init();
  MX_TIM3_Init();
  MX_TIM4_Init();
  MX_TIM5_Init();
  MX_TIM15_Init();
  MX_USART2_UART_Init();
  MX_FATFS_Init();
  MX_RNG_Init();
  MX_TIM7_Init();
  MX_TIM2_Init();
  MX_TIM6_Init();
  MX_TIM13_Init();
  MX_TIM14_Init();
  MX_LPTIM3_Init();
  MX_LPTIM4_Init();
  /* USER CODE BEGIN 2 */
	HAL_GPIO_WritePin(SENSOR_IR_EN_GPIO_Port, SENSOR_IR_EN_Pin, GPIO_PIN_SET);
	HAL_GPIO_WritePin(SENSOR_PT_EN_GPIO_Port, SENSOR_PT_EN_Pin, GPIO_PIN_SET);

	HAL_GPIO_WritePin(SENSOR_LED_L_GPIO_Port, SENSOR_LED_L_Pin, GPIO_PIN_SET);
	HAL_GPIO_WritePin(SENSOR_LED_R_GPIO_Port, SENSOR_LED_R_Pin, GPIO_PIN_SET);
	User_Init();
	HAL_GPIO_WritePin(SENSOR_LED_L_GPIO_Port, SENSOR_LED_L_Pin, GPIO_PIN_RESET);
	HAL_GPIO_WritePin(SENSOR_LED_R_GPIO_Port, SENSOR_LED_R_Pin, GPIO_PIN_RESET);
	LED_OFF;
  /* USER CODE END 2 */

  /* Infinite loop */
  /* USER CODE BEGIN WHILE */
	LCD_Clear();
	while (1) {
    /* USER CODE END WHILE */

    /* USER CODE BEGIN 3 */
		Menu_ProcessLoop();
	}
  /* USER CODE END 3 */
}

void SystemClock_Config(void)
{
  RCC_OscInitTypeDef RCC_OscInitStruct = {0};
  RCC_ClkInitTypeDef RCC_ClkInitStruct = {0};

  /** Supply configuration update enable
  */
  HAL_PWREx_ConfigSupply(PWR_LDO_SUPPLY);

  /** Configure the main internal regulator output voltage
  */
  __HAL_PWR_VOLTAGESCALING_CONFIG(PWR_REGULATOR_VOLTAGE_SCALE0);

  while(!__HAL_PWR_GET_FLAG(PWR_FLAG_VOSRDY)) {}

  /** Configure LSE Drive Capability
  */
  HAL_PWR_EnableBkUpAccess();
  __HAL_RCC_LSEDRIVE_CONFIG(RCC_LSEDRIVE_HIGH);

  /** Initializes the RCC Oscillators according to the specified parameters
  * in the RCC_OscInitTypeDef structure.
  */
  RCC_OscInitStruct.OscillatorType = RCC_OSCILLATORTYPE_HSI48|RCC_OSCILLATORTYPE_LSI
                              |RCC_OSCILLATORTYPE_HSE|RCC_OSCILLATORTYPE_LSE;
  RCC_OscInitStruct.HSEState = RCC_HSE_ON;
  RCC_OscInitStruct.LSEState = RCC_LSE_ON;
  RCC_OscInitStruct.LSIState = RCC_LSI_ON;
  RCC_OscInitStruct.HSI48State = RCC_HSI48_ON;
  RCC_OscInitStruct.PLL.PLLState = RCC_PLL_ON;
  RCC_OscInitStruct.PLL.PLLSource = RCC_PLLSOURCE_HSE;
  RCC_OscInitStruct.PLL.PLLM = 5;
  RCC_OscInitStruct.PLL.PLLN = 192;
  RCC_OscInitStruct.PLL.PLLP = 2;
  RCC_OscInitStruct.PLL.PLLQ = 12;
  RCC_OscInitStruct.PLL.PLLR = 2;
  RCC_OscInitStruct.PLL.PLLRGE = RCC_PLL1VCIRANGE_2;
  RCC_OscInitStruct.PLL.PLLVCOSEL = RCC_PLL1VCOWIDE;
  RCC_OscInitStruct.PLL.PLLFRACN = 0;
  if (HAL_RCC_OscConfig(&RCC_OscInitStruct) != HAL_OK)
  {
    Error_Handler();
  }

  /** Initializes the CPU, AHB and APB buses clocks
  */
  RCC_ClkInitStruct.ClockType = RCC_CLOCKTYPE_HCLK|RCC_CLOCKTYPE_SYSCLK
                              |RCC_CLOCKTYPE_PCLK1|RCC_CLOCKTYPE_PCLK2
                              |RCC_CLOCKTYPE_D3PCLK1|RCC_CLOCKTYPE_D1PCLK1;
  RCC_ClkInitStruct.SYSCLKSource = RCC_SYSCLKSOURCE_PLLCLK;
  RCC_ClkInitStruct.SYSCLKDivider = RCC_SYSCLK_DIV1;
  RCC_ClkInitStruct.AHBCLKDivider = RCC_HCLK_DIV2;
  RCC_ClkInitStruct.APB3CLKDivider = RCC_APB3_DIV2;
  RCC_ClkInitStruct.APB1CLKDivider = RCC_APB1_DIV2;
  RCC_ClkInitStruct.APB2CLKDivider = RCC_APB2_DIV2;
  RCC_ClkInitStruct.APB4CLKDivider = RCC_APB4_DIV2;

  if (HAL_RCC_ClockConfig(&RCC_ClkInitStruct, FLASH_LATENCY_4) != HAL_OK)
  {
    Error_Handler();
  }
}

void PeriphCommonClock_Config(void)
{
  RCC_PeriphCLKInitTypeDef PeriphClkInitStruct = {0};

  /** Initializes the peripherals clock
  */
  PeriphClkInitStruct.PeriphClockSelection = RCC_PERIPHCLK_ADC;
  PeriphClkInitStruct.PLL2.PLL2M = 2;
  PeriphClkInitStruct.PLL2.PLL2N = 40;
  PeriphClkInitStruct.PLL2.PLL2P = 5;
  PeriphClkInitStruct.PLL2.PLL2Q = 2;
  PeriphClkInitStruct.PLL2.PLL2R = 2;
  PeriphClkInitStruct.PLL2.PLL2RGE = RCC_PLL2VCIRANGE_3;
  PeriphClkInitStruct.PLL2.PLL2VCOSEL = RCC_PLL2VCOWIDE;
  PeriphClkInitStruct.PLL2.PLL2FRACN = 0;
  PeriphClkInitStruct.AdcClockSelection = RCC_ADCCLKSOURCE_PLL2;
  if (HAL_RCCEx_PeriphCLKConfig(&PeriphClkInitStruct) != HAL_OK)
  {
    Error_Handler();
  }
}

 /* MPU Configuration */

void MPU_Config(void)
{
  MPU_Region_InitTypeDef MPU_InitStruct = {0};

  /* Disables the MPU */
  HAL_MPU_Disable();

  /** Initializes and configures the Region and the memory to be protected
  */
  MPU_InitStruct.Enable = MPU_REGION_ENABLE;
  MPU_InitStruct.Number = MPU_REGION_NUMBER0;
  MPU_InitStruct.BaseAddress = 0x30040000;
  MPU_InitStruct.Size = MPU_REGION_SIZE_32KB;
  MPU_InitStruct.SubRegionDisable = 0x0;
  MPU_InitStruct.TypeExtField = MPU_TEX_LEVEL1;
  MPU_InitStruct.AccessPermission = MPU_REGION_FULL_ACCESS;
  MPU_InitStruct.DisableExec = MPU_INSTRUCTION_ACCESS_DISABLE;
  MPU_InitStruct.IsShareable = MPU_ACCESS_SHAREABLE;
  MPU_InitStruct.IsCacheable = MPU_ACCESS_NOT_CACHEABLE;
  MPU_InitStruct.IsBufferable = MPU_ACCESS_NOT_BUFFERABLE;

  HAL_MPU_ConfigRegion(&MPU_InitStruct);

  /** Initializes and configures the Region and the memory to be protected
  */
  MPU_InitStruct.Number = MPU_REGION_NUMBER1;
  MPU_InitStruct.BaseAddress = 0x38000000;
  MPU_InitStruct.Size = MPU_REGION_SIZE_64KB;

  HAL_MPU_ConfigRegion(&MPU_InitStruct);
  /* Enables the MPU */
  HAL_MPU_Enable(MPU_PRIVILEGED_DEFAULT);

}

void Error_Handler(void)
{
	__disable_irq();
	while (1) {
	}
}
